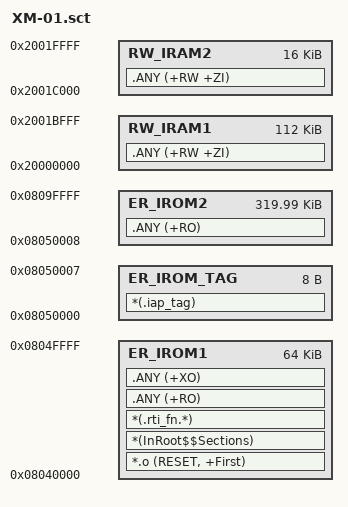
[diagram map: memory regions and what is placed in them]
; *************************************************************
; *** Scatter-Loading Description File generated by uVision ***
; *************************************************************

LR_IROM1 0x08040000 0x00010000  {    ; load region size_region
  ER_IROM1 0x08040000 0x00010000  {  ; load address = execution address
   *.o (RESET, +First)
   *(InRoot$$Sections)
   *(.rti_fn.*)                      ; RT_thread初始化
   .ANY (+RO)                        
   .ANY (+XO)
  }
  RW_IRAM1 0x20000000 0x0001C000  {  ; RW data
   .ANY (+RW +ZI)
  }
  RW_IRAM2 0x2001C000 0x00004000  {
   .ANY (+RW +ZI)
  }
}

; 为IAP标签专门分配精确的8字节空间
LR_IROM_TAG 0x08050000 0x00000008  {  ; 精确分配8字节
  ER_IROM_TAG 0x08050000 0x00000008  {
   *(.iap_tag)  ; 自定义段名称
  }
}

LR_IROM2 0x08050008 0x0004FFF8  {  ; 紧接标签后开始，充分利用剩余空间
  ER_IROM2 0x08050008 0x0004FFF8  {  ; load address = execution address
   .ANY (+RO)
  }
}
